AUTOSAR XML (schema 00046)
package /RTE_Event_Lab
  sender receiver interface Get_Paramaters
    data Var1: type=uint16
    data Var2: type=uint16
  sender receiver interface Get_Result
    data Result: type=uint32
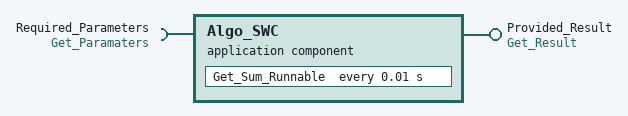
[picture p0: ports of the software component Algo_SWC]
  application sw component type Algo_SWC
    require port Required_Parameters: required-interface=Get_Paramaters
    provide port Provided_Result: provided-interface=Get_Result
    behavior SWC_Beh
      timing event Timing_Event: start-on-event=Get_Sum_Runnable, period=0.01
      data received event Data_Received: start-on-event=Get_Sum_Runnable, data=Required_Parameters.Var1
      data send completed event Result_Sent: start-on-event=Get_Sum_Runnable, event-source=Result
      init event Init: start-on-event=Get_Sum_Runnable
      runnable Get_Sum_Runnable: symbol=GetSum
        data-read-access:
          access Variable1: accessed-variable=Required_Parameters.Var1
          access Variable2: accessed-variable=Required_Parameters.Var2
        data-write-access:
          access Result: accessed-variable=Provided_Result.Result
